AUTOSAR XML (schema 00046)
package /jmc_auto/ModuleServices/Control
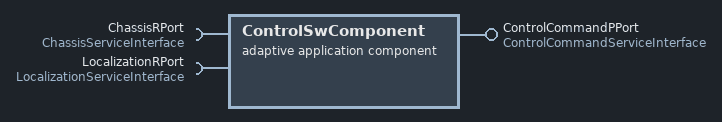
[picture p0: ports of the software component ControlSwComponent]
  adaptive application sw component type ControlSwComponent
    require port ChassisRPort: required-interface=ChassisServiceInterface
    provide port ControlCommandPPort: provided-interface=ControlCommandServiceInterface
    require port LocalizationRPort: required-interface=LocalizationServiceInterface
package /jmc_auto/ModuleServices/ControlExecutable
  executable ControlExecutable
    root sw component prototype ControlRootSwComponent: application-type=ControlSwComponent
